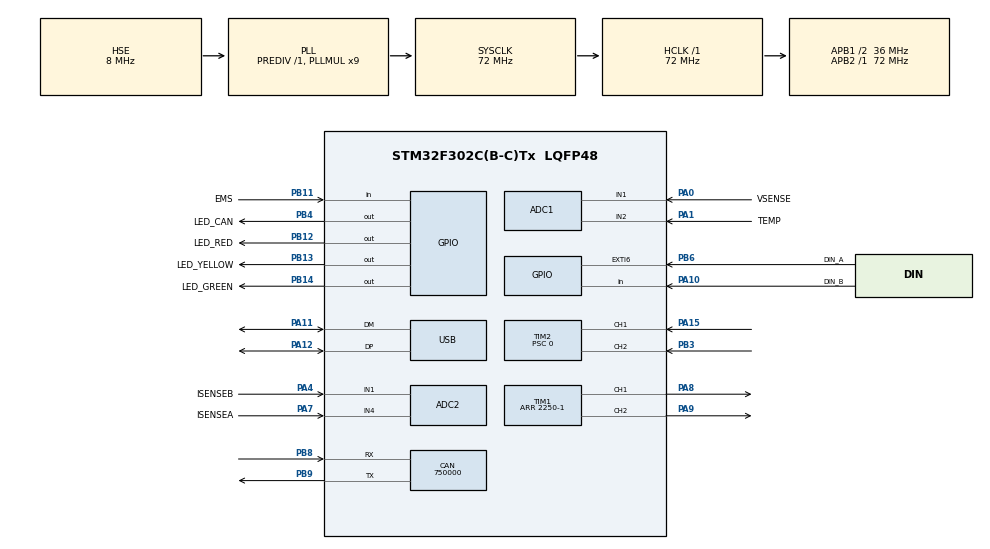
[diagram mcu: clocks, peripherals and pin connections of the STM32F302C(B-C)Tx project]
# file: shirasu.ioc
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ADC1.EnableInjectedConversion=ENABLE
ADC1.EnableRegularConversion=DISABLE
ADC1.InjNumberOfConversion=2
ADC1.InjectedChannel-3\#ChannelInjectedConversion=ADC_CHANNEL_1
ADC1.InjectedChannel-4\#ChannelInjectedConversion=ADC_CHANNEL_2
ADC1.InjectedOffset-3\#ChannelInjectedConversion=0
ADC1.InjectedOffset-4\#ChannelInjectedConversion=0
ADC1.InjectedOffsetNumber-3\#ChannelInjectedConversion=ADC_OFFSET_NONE
ADC1.InjectedOffsetNumber-4\#ChannelInjectedConversion=ADC_OFFSET_NONE
ADC1.InjectedRank-3\#ChannelInjectedConversion=1
ADC1.InjectedRank-4\#ChannelInjectedConversion=2
ADC1.InjectedSamplingTime-3\#ChannelInjectedConversion=ADC_SAMPLETIME_601CYCLES_5
ADC1.InjectedSamplingTime-4\#ChannelInjectedConversion=ADC_SAMPLETIME_601CYCLES_5
ADC1.InjectedSamplingTimeOPAMP-3\#ChannelInjectedConversion=ADC_SAMPLETIME_61CYCLES_5
ADC1.InjectedSamplingTimeOPAMP-4\#ChannelInjectedConversion=ADC_SAMPLETIME_61CYCLES_5
ADC1.Rank1_Channel=ADC_CHANNEL_1
ADC1.Rank2_Channel=ADC_CHANNEL_2
ADC1.master=1
ADC2.ClockPrescaler=ADC_CLOCK_ASYNC_DIV1
ADC2.ContinuousConvMode=ENABLE
ADC2.DMAContinuousRequests=DISABLE
ADC2.EOCSelection=ADC_EOC_SINGLE_CONV
ADC2.EnableAnalogWatchDog1=false
ADC2.EnableInjectedConversion=ENABLE
ADC2.EnableRegularConversion=DISABLE
ADC2.ExternalTrigInjecConv=ADC_EXTERNALTRIGINJECCONV_T1_TRGO
ADC2.ExternalTrigInjecConvEdge=ADC_EXTERNALTRIGINJECCONV_EDGE_FALLING
ADC2.InjNumberOfConversion=2
ADC2.InjectedChannel-3\#ChannelInjectedConversion=ADC_CHANNEL_1
ADC2.InjectedChannel-4\#ChannelInjectedConversion=ADC_CHANNEL_4
ADC2.InjectedConvMode=None
ADC2.InjectedOffset-3\#ChannelInjectedConversion=0
ADC2.InjectedOffset-4\#ChannelInjectedConversion=0
ADC2.InjectedOffsetNumber-3\#ChannelInjectedConversion=ADC_OFFSET_NONE
ADC2.InjectedOffsetNumber-4\#ChannelInjectedConversion=ADC_OFFSET_NONE
ADC2.InjectedRank-3\#ChannelInjectedConversion=1
ADC2.InjectedRank-4\#ChannelInjectedConversion=2
ADC2.InjectedSamplingTime-3\#ChannelInjectedConversion=ADC_SAMPLETIME_19CYCLES_5
ADC2.InjectedSamplingTime-4\#ChannelInjectedConversion=ADC_SAMPLETIME_19CYCLES_5
ADC2.InjectedSamplingTimeOPAMP-3\#ChannelInjectedConversion=ADC_SAMPLETIME_19CYCLES_5
ADC2.InjectedSamplingTimeOPAMP-4\#ChannelInjectedConversion=ADC_SAMPLETIME_61CYCLES_5
ADC2.Mode=ADC_MODE_INDEPENDENT
ADC2.Rank2_Channel=ADC_CHANNEL_4
CAN.CalculateBaudRate=750000
CAN.CalculateTimeBit=1333.33
CAN.CalculateTimeQuantum=444.44444444444446
Mcu.Family=STM32F3
Mcu.Name=STM32F302C(B-C)Tx
Mcu.Package=LQFP48
NVIC.ADC1_2_IRQn=true\:0\:0\:false\:false\:true\:true\:true
NVIC.EXTI9_5_IRQn=true\:0\:0\:false\:false\:true\:true\:true
NVIC.PriorityGroup=NVIC_PRIORITYGROUP_4
NVIC.TIM3_IRQn=true\:2\:0\:true\:false\:true\:true\:true
NVIC.USB_LP_CAN_RX0_IRQn=true\:0\:0\:true\:false\:true\:true\:true
NVIC.USB_LP_IRQn=true\:1\:0\:true\:false\:true\:false\:true
PA0.GPIO_Label=VSENSE
PA0.Mode=IN1-Single-Ended
PA0.Signal=ADC1_IN1
PA1.GPIO_Label=TEMP
PA1.Mode=IN2-Single-Ended
PA1.Signal=ADC1_IN2
PA10.GPIO_Label=DIN_B
PA10.GPIO_PuPd=GPIO_PULLDOWN
PA10.Signal=GPIO_Input
PA11.Mode=Device
PA11.Signal=USB_DM
PA12.Mode=Device
PA12.Signal=USB_DP
PA13.Mode=Serial_Wire
PA13.Signal=SYS_JTMS-SWDIO
PA14.Mode=Serial_Wire
PA14.Signal=SYS_JTCK-SWCLK
PA15.GPIO_PuPd=GPIO_PULLUP
PA15.Signal=S_TIM2_CH1_ETR
PA4.GPIO_Label=ISENSEB
PA4.Mode=IN1-Single-Ended
PA4.Signal=ADC2_IN1
PA7.GPIO_Label=ISENSEA
PA7.Mode=IN4-Single-Ended
PA7.Signal=ADC2_IN4
PA8.Signal=S_TIM1_CH1
PA9.Signal=S_TIM1_CH2
PB0.Signal=COMP4_INP
PB11.GPIO_Label=EMS
PB11.GPIO_PuPd=GPIO_PULLDOWN
PB11.Signal=GPIO_Input
PB12.GPIO_Label=LED_RED
PB12.Signal=GPIO_Output
PB13.GPIO_Label=LED_YELLOW
PB13.Signal=GPIO_Output
PB14.GPIO_Label=LED_GREEN
PB14.Signal=GPIO_Output
PB3.GPIO_PuPd=GPIO_PULLUP
PB3.Signal=S_TIM2_CH2
PB4.GPIO_Label=LED_CAN
PB4.Signal=GPIO_Output
PB6.GPIO_Label=DIN_A
PB6.GPIO_ModeDefaultEXTI=GPIO_MODE_IT_FALLING
PB6.GPIO_PuPd=GPIO_PULLDOWN
PB6.Signal=GPXTI6
PB8.Mode=CAN_Activate
PB8.Signal=CAN_RX
PB9.Mode=CAN_Activate
PB9.Signal=CAN_TX
PF0-OSC_IN.Mode=HSE-External-Oscillator
PF0-OSC_IN.Signal=RCC_OSC_IN
PF1-OSC_OUT.Mode=HSE-External-Oscillator
PF1-OSC_OUT.Signal=RCC_OSC_OUT
ProjectManager.HeapSize=0x200
ProjectManager.StackSize=0x400
ProjectManager.TargetToolchain=STM32CubeIDE
RCC.AHBFreq_Value=72000000
RCC.APB1CLKDivider=RCC_HCLK_DIV2
RCC.APB1Freq_Value=36000000
RCC.APB1TimFreq_Value=72000000
RCC.APB2Freq_Value=72000000
RCC.APB2TimFreq_Value=72000000
RCC.CortexFreq_Value=72000000
RCC.HCLKFreq_Value=72000000
RCC.HSE_VALUE=8000000
RCC.HSI_VALUE=8000000
RCC.LSE_VALUE=32768
RCC.PLLMUL=RCC_PLL_MUL9
RCC.PRESCALERUSB=RCC_USBCLKSOURCE_PLL_DIV1_5
RCC.SYSCLKFreq_VALUE=72000000
RCC.SYSCLKSourceVirtual=RCC_SYSCLKSOURCE_PLLCLK
RCC.USBFreq_Value=48000000
SH.S_TIM1_CH1.0=TIM1_CH1,PWM Generation1 CH1
SH.S_TIM1_CH2.0=TIM1_CH2,PWM Generation2 CH2
SH.S_TIM2_CH1_ETR.0=TIM2_CH1,Encoder_Interface
SH.S_TIM2_CH2.0=TIM2_CH2,Encoder_Interface
TIM1.AutoReloadPreload=TIM_AUTORELOAD_PRELOAD_ENABLE
TIM1.AutomaticOutput=TIM_AUTOMATICOUTPUT_ENABLE
TIM1.Break2Filter=0xF
TIM1.Break2State=TIM_BREAK2_ENABLE
TIM1.BreakFilter=0xF
TIM1.BreakState=TIM_BREAK_ENABLE
TIM1.Channel-PWM\ Generation1\ CH1=TIM_CHANNEL_1
TIM1.Channel-PWM\ Generation2\ CH2=TIM_CHANNEL_2
TIM1.Channel-PWM\ Generation3\ No\ Output=TIM_CHANNEL_3
TIM1.ClockDivision=TIM_CLOCKDIVISION_DIV4
TIM1.CounterMode=TIM_COUNTERMODE_CENTERALIGNED1
TIM1.OCPolarity_3=TIM_OCPOLARITY_LOW
TIM1.Period=2250-1
TIM1.TIM_MasterOutputTrigger=TIM_TRGO_OC3REF
TIM1.TIM_MasterOutputTrigger2=TIM_TRGO2_UPDATE
TIM2.EncoderMode=TIM_ENCODERMODE_TI12
TIM2.IC1Filter=0x9
TIM2.IC2Filter=0x9
TIM2.Prescaler=0
TIM3.AutoReloadPreload=TIM_AUTORELOAD_PRELOAD_ENABLE
TIM3.Period=1000-1
TIM3.Prescaler=2400-1
USB_DEVICE.CLASS_NAME_FS=CDC
USB_DEVICE.VirtualMode=Cdc
USB_DEVICE.VirtualModeFS=Cdc_FS
VP_TIM1_VS_ClockSourceINT.Mode=Internal
VP_TIM1_VS_no_output3.Mode=PWM Generation3 No Output
VP_TIM3_VS_ClockSourceINT.Mode=Internal
VP_USB_DEVICE_VS_USB_DEVICE_CDC_FS.Mode=CDC_FS
board=custom

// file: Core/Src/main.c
/* USER CODE BEGIN Header */
/**
  ******************************************************************************
  * @file           : main.c
  * @brief          : Main program body
  ******************************************************************************
  * @attention
  *
  * <h2><center>&copy; Copyright (c) 2020 STMicroelectronics.
  * All rights reserved.</center></h2>
  *
  * This software component is licensed by ST under BSD 3-Clause license,
  * the "License"; You may not use this file except in compliance with the
  * License. You may obtain a copy of the License at:
  *                        opensource.org/licenses/BSD-3-Clause
  *
  ******************************************************************************
  */
/* USER CODE END Header */
#include "main.h"
#include "usb_device.h"

ADC_HandleTypeDef hadc1;
ADC_HandleTypeDef hadc2;

CAN_HandleTypeDef hcan;

TIM_HandleTypeDef htim1;
TIM_HandleTypeDef htim2;
TIM_HandleTypeDef htim3;

void SystemClock_Config(void);
static void MX_GPIO_Init(void);
static void MX_ADC2_Init(void);
static void MX_CAN_Init(void);
static void MX_TIM2_Init(void);
static void MX_ADC1_Init(void);
static void MX_TIM1_Init(void);
static void MX_TIM3_Init(void);

int main(void)
{

  /* MCU Configuration--------------------------------------------------------*/

  /* Reset of all peripherals, Initializes the Flash interface and the Systick. */
  HAL_Init();

  /* Configure the system clock */
  SystemClock_Config();

  /* Initialize all configured peripherals */
  MX_GPIO_Init();
  MX_USB_DEVICE_Init();
  MX_ADC2_Init();
  MX_CAN_Init();
  MX_TIM2_Init();
  MX_ADC1_Init();
  MX_TIM1_Init();
  MX_TIM3_Init();
  /* USER CODE BEGIN 2 */
  main_cpp();
  /* USER CODE END 2 */

  /* Infinite loop */

}

void SystemClock_Config(void)
{
  RCC_OscInitTypeDef RCC_OscInitStruct = {0};
  RCC_ClkInitTypeDef RCC_ClkInitStruct = {0};
  RCC_PeriphCLKInitTypeDef PeriphClkInit = {0};

  /** Initializes the RCC Oscillators according to the specified parameters
  * in the RCC_OscInitTypeDef structure.
  */
  RCC_OscInitStruct.OscillatorType = RCC_OSCILLATORTYPE_HSE;
  RCC_OscInitStruct.HSEState = RCC_HSE_ON;
  RCC_OscInitStruct.HSEPredivValue = RCC_HSE_PREDIV_DIV1;
  RCC_OscInitStruct.HSIState = RCC_HSI_ON;
  RCC_OscInitStruct.PLL.PLLState = RCC_PLL_ON;
  RCC_OscInitStruct.PLL.PLLSource = RCC_PLLSOURCE_HSE;
  RCC_OscInitStruct.PLL.PLLMUL = RCC_PLL_MUL9;
  if (HAL_RCC_OscConfig(&RCC_OscInitStruct) != HAL_OK)
  {
    Error_Handler();
  }
  /** Initializes the CPU, AHB and APB buses clocks
  */
  RCC_ClkInitStruct.ClockType = RCC_CLOCKTYPE_HCLK|RCC_CLOCKTYPE_SYSCLK
                              |RCC_CLOCKTYPE_PCLK1|RCC_CLOCKTYPE_PCLK2;
  RCC_ClkInitStruct.SYSCLKSource = RCC_SYSCLKSOURCE_PLLCLK;
  RCC_ClkInitStruct.AHBCLKDivider = RCC_SYSCLK_DIV1;
  RCC_ClkInitStruct.APB1CLKDivider = RCC_HCLK_DIV2;
  RCC_ClkInitStruct.APB2CLKDivider = RCC_HCLK_DIV1;

  if (HAL_RCC_ClockConfig(&RCC_ClkInitStruct, FLASH_LATENCY_2) != HAL_OK)
  {
    Error_Handler();
  }
  PeriphClkInit.PeriphClockSelection = RCC_PERIPHCLK_USB|RCC_PERIPHCLK_TIM1
                              |RCC_PERIPHCLK_ADC12;
  PeriphClkInit.Adc12ClockSelection = RCC_ADC12PLLCLK_DIV1;
  PeriphClkInit.USBClockSelection = RCC_USBCLKSOURCE_PLL_DIV1_5;
  PeriphClkInit.Tim1ClockSelection = RCC_TIM1CLK_HCLK;
  if (HAL_RCCEx_PeriphCLKConfig(&PeriphClkInit) != HAL_OK)
  {
    Error_Handler();
  }
}

static void MX_ADC1_Init(void)
{

  ADC_MultiModeTypeDef multimode = {0};
  ADC_InjectionConfTypeDef sConfigInjected = {0};

  /** Common config
  */
  hadc1.Instance = ADC1;
  hadc1.Init.ClockPrescaler = ADC_CLOCK_ASYNC_DIV1;
  hadc1.Init.Resolution = ADC_RESOLUTION_12B;
  hadc1.Init.ScanConvMode = ADC_SCAN_ENABLE;
  hadc1.Init.ContinuousConvMode = DISABLE;
  hadc1.Init.DiscontinuousConvMode = DISABLE;
  hadc1.Init.DataAlign = ADC_DATAALIGN_RIGHT;
  hadc1.Init.NbrOfConversion = 1;
  hadc1.Init.DMAContinuousRequests = DISABLE;
  hadc1.Init.EOCSelection = ADC_EOC_SINGLE_CONV;
  hadc1.Init.LowPowerAutoWait = DISABLE;
  hadc1.Init.Overrun = ADC_OVR_DATA_OVERWRITTEN;
  if (HAL_ADC_Init(&hadc1) != HAL_OK)
  {
    Error_Handler();
  }
  /** Configure the ADC multi-mode
  */
  multimode.Mode = ADC_MODE_INDEPENDENT;
  if (HAL_ADCEx_MultiModeConfigChannel(&hadc1, &multimode) != HAL_OK)
  {
    Error_Handler();
  }
  /** Configure Injected Channel
  */
  sConfigInjected.InjectedChannel = ADC_CHANNEL_1;
  sConfigInjected.InjectedRank = ADC_INJECTED_RANK_1;
  sConfigInjected.InjectedSingleDiff = ADC_SINGLE_ENDED;
  sConfigInjected.InjectedNbrOfConversion = 2;
  sConfigInjected.InjectedSamplingTime = ADC_SAMPLETIME_601CYCLES_5;
  sConfigInjected.ExternalTrigInjecConvEdge = ADC_EXTERNALTRIGINJECCONV_EDGE_RISING;
  sConfigInjected.ExternalTrigInjecConv = ADC_INJECTED_SOFTWARE_START;
  sConfigInjected.AutoInjectedConv = DISABLE;
  sConfigInjected.InjectedDiscontinuousConvMode = DISABLE;
  sConfigInjected.QueueInjectedContext = DISABLE;
  sConfigInjected.InjectedOffset = 0;
  sConfigInjected.InjectedOffsetNumber = ADC_OFFSET_NONE;
  if (HAL_ADCEx_InjectedConfigChannel(&hadc1, &sConfigInjected) != HAL_OK)
  {
    Error_Handler();
  }
  /** Configure Injected Channel
  */
  sConfigInjected.InjectedChannel = ADC_CHANNEL_2;
  sConfigInjected.InjectedRank = ADC_INJECTED_RANK_2;
  if (HAL_ADCEx_InjectedConfigChannel(&hadc1, &sConfigInjected) != HAL_OK)
  {
    Error_Handler();
  }

}

static void MX_ADC2_Init(void)
{

  ADC_InjectionConfTypeDef sConfigInjected = {0};

  /** Common config
  */
  hadc2.Instance = ADC2;
  hadc2.Init.ClockPrescaler = ADC_CLOCK_ASYNC_DIV1;
  hadc2.Init.Resolution = ADC_RESOLUTION_12B;
  hadc2.Init.ScanConvMode = ADC_SCAN_ENABLE;
  hadc2.Init.ContinuousConvMode = ENABLE;
  hadc2.Init.DiscontinuousConvMode = DISABLE;
  hadc2.Init.DataAlign = ADC_DATAALIGN_RIGHT;
  hadc2.Init.NbrOfConversion = 1;
  hadc2.Init.DMAContinuousRequests = DISABLE;
  hadc2.Init.EOCSelection = ADC_EOC_SINGLE_CONV;
  hadc2.Init.LowPowerAutoWait = DISABLE;
  hadc2.Init.Overrun = ADC_OVR_DATA_OVERWRITTEN;
  if (HAL_ADC_Init(&hadc2) != HAL_OK)
  {
    Error_Handler();
  }
  /** Configure Injected Channel
  */
  sConfigInjected.InjectedChannel = ADC_CHANNEL_2;
  sConfigInjected.InjectedRank = ADC_INJECTED_RANK_1;
  sConfigInjected.InjectedSingleDiff = ADC_SINGLE_ENDED;
  sConfigInjected.InjectedNbrOfConversion = 2;
  sConfigInjected.InjectedSamplingTime = ADC_SAMPLETIME_19CYCLES_5;
  sConfigInjected.ExternalTrigInjecConvEdge = ADC_EXTERNALTRIGINJECCONV_EDGE_FALLING;
  sConfigInjected.ExternalTrigInjecConv = ADC_EXTERNALTRIGINJECCONV_T1_TRGO;
  sConfigInjected.AutoInjectedConv = DISABLE;
  sConfigInjected.InjectedDiscontinuousConvMode = DISABLE;
  sConfigInjected.QueueInjectedContext = DISABLE;
  sConfigInjected.InjectedOffset = 0;
  sConfigInjected.InjectedOffsetNumber = ADC_OFFSET_NONE;
  if (HAL_ADCEx_InjectedConfigChannel(&hadc2, &sConfigInjected) != HAL_OK)
  {
    Error_Handler();
  }
  /** Configure Injected Channel
  */
  sConfigInjected.InjectedChannel = ADC_CHANNEL_4;
  sConfigInjected.InjectedRank = ADC_INJECTED_RANK_2;
  if (HAL_ADCEx_InjectedConfigChannel(&hadc2, &sConfigInjected) != HAL_OK)
  {
    Error_Handler();
  }

}

static void MX_CAN_Init(void)
{

  hcan.Instance = CAN;
  hcan.Init.Prescaler = 16;
  hcan.Init.Mode = CAN_MODE_NORMAL;
  hcan.Init.SyncJumpWidth = CAN_SJW_1TQ;
  hcan.Init.TimeSeg1 = CAN_BS1_1TQ;
  hcan.Init.TimeSeg2 = CAN_BS2_1TQ;
  hcan.Init.TimeTriggeredMode = DISABLE;
  hcan.Init.AutoBusOff = DISABLE;
  hcan.Init.AutoWakeUp = DISABLE;
  hcan.Init.AutoRetransmission = DISABLE;
  hcan.Init.ReceiveFifoLocked = DISABLE;
  hcan.Init.TransmitFifoPriority = DISABLE;
  if (HAL_CAN_Init(&hcan) != HAL_OK)
  {
    Error_Handler();
  }

}

static void MX_TIM1_Init(void)
{

  TIM_ClockConfigTypeDef sClockSourceConfig = {0};
  TIM_MasterConfigTypeDef sMasterConfig = {0};
  TIM_OC_InitTypeDef sConfigOC = {0};
  TIM_BreakDeadTimeConfigTypeDef sBreakDeadTimeConfig = {0};

  htim1.Instance = TIM1;
  htim1.Init.Prescaler = 0;
  htim1.Init.CounterMode = TIM_COUNTERMODE_CENTERALIGNED1;
  htim1.Init.Period = 2250-1;
  htim1.Init.ClockDivision = TIM_CLOCKDIVISION_DIV4;
  htim1.Init.RepetitionCounter = 0;
  htim1.Init.AutoReloadPreload = TIM_AUTORELOAD_PRELOAD_ENABLE;
  if (HAL_TIM_Base_Init(&htim1) != HAL_OK)
  {
    Error_Handler();
  }
  sClockSourceConfig.ClockSource = TIM_CLOCKSOURCE_INTERNAL;
  if (HAL_TIM_ConfigClockSource(&htim1, &sClockSourceConfig) != HAL_OK)
  {
    Error_Handler();
  }
  if (HAL_TIM_PWM_Init(&htim1) != HAL_OK)
  {
    Error_Handler();
  }
  sMasterConfig.MasterOutputTrigger = TIM_TRGO_OC3REF;
  sMasterConfig.MasterOutputTrigger2 = TIM_TRGO2_UPDATE;
  sMasterConfig.MasterSlaveMode = TIM_MASTERSLAVEMODE_DISABLE;
  if (HAL_TIMEx_MasterConfigSynchronization(&htim1, &sMasterConfig) != HAL_OK)
  {
    Error_Handler();
  }
  sConfigOC.OCMode = TIM_OCMODE_PWM1;
  sConfigOC.Pulse = 0;
  sConfigOC.OCPolarity = TIM_OCPOLARITY_HIGH;
  sConfigOC.OCNPolarity = TIM_OCNPOLARITY_HIGH;
  sConfigOC.OCFastMode = TIM_OCFAST_DISABLE;
  sConfigOC.OCIdleState = TIM_OCIDLESTATE_RESET;
  sConfigOC.OCNIdleState = TIM_OCNIDLESTATE_RESET;
  if (HAL_TIM_PWM_ConfigChannel(&htim1, &sConfigOC, TIM_CHANNEL_1) != HAL_OK)
  {
    Error_Handler();
  }
  if (HAL_TIM_PWM_ConfigChannel(&htim1, &sConfigOC, TIM_CHANNEL_2) != HAL_OK)
  {
    Error_Handler();
  }
  sConfigOC.OCPolarity = TIM_OCPOLARITY_LOW;
  if (HAL_TIM_PWM_ConfigChannel(&htim1, &sConfigOC, TIM_CHANNEL_3) != HAL_OK)
  {
    Error_Handler();
  }
  sBreakDeadTimeConfig.OffStateRunMode = TIM_OSSR_DISABLE;
  sBreakDeadTimeConfig.OffStateIDLEMode = TIM_OSSI_DISABLE;
  sBreakDeadTimeConfig.LockLevel = TIM_LOCKLEVEL_OFF;
  sBreakDeadTimeConfig.DeadTime = 0;
  sBreakDeadTimeConfig.BreakState = TIM_BREAK_ENABLE;
  sBreakDeadTimeConfig.BreakPolarity = TIM_BREAKPOLARITY_HIGH;
  sBreakDeadTimeConfig.BreakFilter = 0xF;
  sBreakDeadTimeConfig.Break2State = TIM_BREAK2_ENABLE;
  sBreakDeadTimeConfig.Break2Polarity = TIM_BREAK2POLARITY_HIGH;
  sBreakDeadTimeConfig.Break2Filter = 0xF;
  sBreakDeadTimeConfig.AutomaticOutput = TIM_AUTOMATICOUTPUT_ENABLE;
  if (HAL_TIMEx_ConfigBreakDeadTime(&htim1, &sBreakDeadTimeConfig) != HAL_OK)
  {
    Error_Handler();
  }
  /* USER CODE BEGIN TIM1_Init 2 */

  //BreakFilter = 0x3 =>8/72M=0.11us

  /* USER CODE END TIM1_Init 2 */
  HAL_TIM_MspPostInit(&htim1);

}

static void MX_TIM2_Init(void)
{

  TIM_Encoder_InitTypeDef sConfig = {0};
  TIM_MasterConfigTypeDef sMasterConfig = {0};

  htim2.Instance = TIM2;
  htim2.Init.Prescaler = 0;
  htim2.Init.CounterMode = TIM_COUNTERMODE_UP;
  htim2.Init.Period = 4294967295;
  htim2.Init.ClockDivision = TIM_CLOCKDIVISION_DIV1;
  htim2.Init.AutoReloadPreload = TIM_AUTORELOAD_PRELOAD_DISABLE;
  sConfig.EncoderMode = TIM_ENCODERMODE_TI12;
  sConfig.IC1Polarity = TIM_ICPOLARITY_RISING;
  sConfig.IC1Selection = TIM_ICSELECTION_DIRECTTI;
  sConfig.IC1Prescaler = TIM_ICPSC_DIV1;
  sConfig.IC1Filter = 0x9;
  sConfig.IC2Polarity = TIM_ICPOLARITY_RISING;
  sConfig.IC2Selection = TIM_ICSELECTION_DIRECTTI;
  sConfig.IC2Prescaler = TIM_ICPSC_DIV1;
  sConfig.IC2Filter = 0x9;
  if (HAL_TIM_Encoder_Init(&htim2, &sConfig) != HAL_OK)
  {
    Error_Handler();
  }
  sMasterConfig.MasterOutputTrigger = TIM_TRGO_RESET;
  sMasterConfig.MasterSlaveMode = TIM_MASTERSLAVEMODE_DISABLE;
  if (HAL_TIMEx_MasterConfigSynchronization(&htim2, &sMasterConfig) != HAL_OK)
  {
    Error_Handler();
  }

}

static void MX_TIM3_Init(void)
{

  TIM_ClockConfigTypeDef sClockSourceConfig = {0};
  TIM_MasterConfigTypeDef sMasterConfig = {0};

  htim3.Instance = TIM3;
  htim3.Init.Prescaler = 2400-1;
  htim3.Init.CounterMode = TIM_COUNTERMODE_UP;
  htim3.Init.Period = 1000-1;
  htim3.Init.ClockDivision = TIM_CLOCKDIVISION_DIV1;
  htim3.Init.AutoReloadPreload = TIM_AUTORELOAD_PRELOAD_ENABLE;
  if (HAL_TIM_Base_Init(&htim3) != HAL_OK)
  {
    Error_Handler();
  }
  sClockSourceConfig.ClockSource = TIM_CLOCKSOURCE_INTERNAL;
  if (HAL_TIM_ConfigClockSource(&htim3, &sClockSourceConfig) != HAL_OK)
  {
    Error_Handler();
  }
  sMasterConfig.MasterOutputTrigger = TIM_TRGO_RESET;
  sMasterConfig.MasterSlaveMode = TIM_MASTERSLAVEMODE_DISABLE;
  if (HAL_TIMEx_MasterConfigSynchronization(&htim3, &sMasterConfig) != HAL_OK)
  {
    Error_Handler();
  }

}

static void MX_GPIO_Init(void)
{
  GPIO_InitTypeDef GPIO_InitStruct = {0};

  /* GPIO Ports Clock Enable */
  __HAL_RCC_GPIOF_CLK_ENABLE();
  __HAL_RCC_GPIOA_CLK_ENABLE();
  __HAL_RCC_GPIOB_CLK_ENABLE();

  /*Configure GPIO pin Output Level */
  HAL_GPIO_WritePin(GPIOB, LED_RED_Pin|LED_YELLOW_Pin|LED_GREEN_Pin|LED_CAN_Pin, GPIO_PIN_RESET);

  /*Configure GPIO pin : EMS_Pin */
  GPIO_InitStruct.Pin = EMS_Pin;
  GPIO_InitStruct.Mode = GPIO_MODE_INPUT;
  GPIO_InitStruct.Pull = GPIO_PULLDOWN;
  HAL_GPIO_Init(EMS_GPIO_Port, &GPIO_InitStruct);

  /*Configure GPIO pins : LED_RED_Pin LED_YELLOW_Pin LED_GREEN_Pin LED_CAN_Pin */
  GPIO_InitStruct.Pin = LED_RED_Pin|LED_YELLOW_Pin|LED_GREEN_Pin|LED_CAN_Pin;
  GPIO_InitStruct.Mode = GPIO_MODE_OUTPUT_PP;
  GPIO_InitStruct.Pull = GPIO_NOPULL;
  GPIO_InitStruct.Speed = GPIO_SPEED_FREQ_LOW;
  HAL_GPIO_Init(GPIOB, &GPIO_InitStruct);

  /*Configure GPIO pin : DIN_B_Pin */
  GPIO_InitStruct.Pin = DIN_B_Pin;
  GPIO_InitStruct.Mode = GPIO_MODE_INPUT;
  GPIO_InitStruct.Pull = GPIO_PULLDOWN;
  HAL_GPIO_Init(DIN_B_GPIO_Port, &GPIO_InitStruct);

  /*Configure GPIO pin : DIN_A_Pin */
  GPIO_InitStruct.Pin = DIN_A_Pin;
  GPIO_InitStruct.Mode = GPIO_MODE_IT_FALLING;
  GPIO_InitStruct.Pull = GPIO_PULLDOWN;
  HAL_GPIO_Init(DIN_A_GPIO_Port, &GPIO_InitStruct);

  /* EXTI interrupt init*/
  HAL_NVIC_SetPriority(EXTI9_5_IRQn, 0, 0);
  HAL_NVIC_EnableIRQ(EXTI9_5_IRQn);

}

void Error_Handler(void)
{
  /* USER CODE BEGIN Error_Handler_Debug */
  /* User can add his own implementation to report the HAL error return state */
	HAL_GPIO_WritePin(LED_RED_GPIO_Port, LED_RED_Pin, GPIO_PIN_SET);
	HAL_GPIO_WritePin(LED_GREEN_GPIO_Port, LED_GREEN_Pin, GPIO_PIN_SET);
	HAL_GPIO_WritePin(LED_YELLOW_GPIO_Port, LED_YELLOW_Pin, GPIO_PIN_SET);
  /* USER CODE END Error_Handler_Debug */
}

/************************ (C) COPYRIGHT STMicroelectronics *****END OF FILE****/
